# TLE985x register map
Vendor: Infineon Technologies AG; File version: 1.3
CPU: CM0 r0p0, little endian, no MPU, no FPU, 2 interrupt priority bits
Registers are 32-bit, read-write, no defined reset value unless marked. A register's access mark holds for its fields unless they carry their own. Offsets are from the block's base; [hi:lo] are bit positions; {n}, {i} and the like mark numbered series; 'fields as' and 'values as' point back to an identical list.

## CCU6
Base 0x4000C000
0x00 CC63R ro — Capture/Compare Register for Channel CC63
  [15:0] CCV — Channel CC63 Compare Value Low Byte
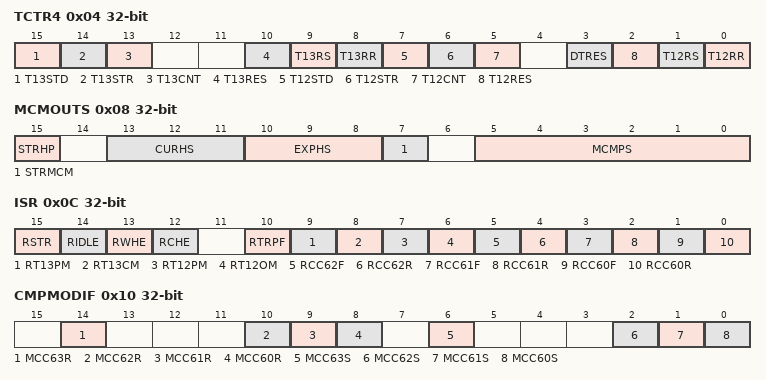
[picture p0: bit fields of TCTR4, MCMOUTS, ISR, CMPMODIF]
0x04 TCTR4 wo — Timer Control Register 4
  [15] T13STD — Timer T13 Shadow Transfer Disable
    0=No action; 1=STE13 reset (STE13 is reset without triggering the shadow transfer.)
  [14] T13STR — Timer T13 Shadow Transfer Request
    0=No action; 1=STE13 set (STE13 is set, enabling the shadow transfer.)
  [13] T13CNT — Timer T13 Count Event
    0=No action; 1=Count (If enabled (PISEL2), timer T13 counts one step.)
  [10] T13RES — Timer T13 Reset
    0=No effect on T13; 1=Zero (The T13 counter register is reset to zero. The switching of the output signals is according to the switching rules. Setting of T13RES has no impact on bit T13R.)
  [9] T13RS — Timer T13 Run Set
    0=No influence (T13R is not influenced.); 1=T13R set (T13R is set, T13 counts.)
  [8] T13RR — Timer T13 Run Reset
    0=No influence (T13R is not influenced.); 1=T13R cleared (T13R is cleared, T13 stops counting.)
  [7] T12STD — Timer T12 Shadow Transfer Disable
    0=No action; 1=STE12 reset (STE12 is reset without triggering the shadow transfer.)
  [6] T12STR — Timer T12 Shadow Transfer Request
    0=No action; 1=STE12 set (STE12 is set, enabling the shadow transfer.)
  [5] T12CNT — Timer T12 Count Event
    0=No action; 1=Count (If enabled (PISEL2), timer T12 counts one step.)
  [3] DTRES — Dead-Time Counter Reset
    0=No effect on the dead-time counters; 1=Zero (The three dead-time counter channels are reset to zero.)
  [2] T12RES — Timer T12 Reset
    0=No effect on T12; 1=Zero (The T12 counter register is reset to zero. The switching of the output signals is according to the switching rules. Setting of T12RES has no impact on bit T12R.)
  [1] T12RS — Timer T12 Run Set
    0=No influence (T12R is not influenced.); 1=T12R set (T12R is set, T12 counts.)
  [0] T12RR — Timer T12 Run Reset
    0=No influence (T12R is not influenced.); 1=T12R cleared (T12R is cleared, T12 stops counting.)
0x08 MCMOUTS access per field — Multi-Channel Mode Output Shadow Register
  [15] STRHP wo — Shadow Transfer Request for the Hall Pattern
    0=by Hardware (The bit fields CURH and EXPH are updated according to the defined hardware action. The write access to bit fields CURHS and EXPHS does not modify the bit fields CURH and EXPH.); 1=by Software (The bit fields CURH and EXPH are updated by the value written to the bit fields CURHS and EXPHS.)
  [13:11] CURHS rw — Current Hall Pattern Shadow
  [10:8] EXPHS rw — Expected Hall Pattern Shadow
  [7] STRMCM wo — Shadow Transfer Request for MCMPS
    0=by Hardware (Bit field MCMP is updated according to the defined hardware action. The write access to bit field MCMPS does not modify bit field MCMP.); 1=by Software (Bit field MCMP is updated by the value written to bit field MCMPS.)
  [5:0] MCMPS rw — Multi-Channel PWM Pattern Shadow
0x0C ISR wo — Capture/Compare Interrupt Status Reset Register
  [15] RSTR — Reset STR Flag
    0=No action; 1=Reset (Bit STR in register IS will be reset.)
  [14] RIDLE — Reset IDLE Flag
    0=No action; 1=Reset (Bit IDLE in register IS will be reset.)
  [13] RWHE — Reset Wrong Hall Event Flag
    0=No action; 1=Reset (Bit WHE in register IS will be reset.)
  [12] RCHE — Reset Correct Hall Event Flag
    0=No action; 1=Reset (Bit CHE in register IS will be reset.)
  [10] RTRPF — Reset Trap Flag
    0=No action; 1=Reset (Bit TRPF in register IS will be reset (not taken into account while input CTRAP = 0 and TRPPEN = 1.)
  [9] RT13PM — Reset Timer T13 Period-Match Flag
    0=No action; 1=Reset (Bit T13PM in register IS will be reset.)
  [8] RT13CM — Reset Timer T13 Compare-Match Flag
    0=No action; 1=Reset (Bit T13CM in register IS will be reset.)
  [7] RT12PM — Reset Timer T12 Period-Match Flag
    0=No action; 1=Reset (Bit T12PM in register IS will be reset.)
  [6] RT12OM — Reset Timer T12 One-Match Flag
    0=No action; 1=Reset (Bit T12OM in register IS will be reset.)
  [5] RCC62F — Reset Capture, Compare-Match Falling Edge Flag
    0=No action; 1=Reset (Bit CC62F in register IS will be reset.)
  [4] RCC62R — Reset Capture, Compare-Match Rising Edge Flag
    0=No action; 1=Reset (Bit CC62R in register IS will be reset.)
  [3] RCC61F — Reset Capture, Compare-Match Falling Edge Flag
    0=No action; 1=Reset (Bit CC61F in register IS will be reset.)
  [2] RCC61R — Reset Capture, Compare-Match Rising Edge Flag
    0=No action; 1=Reset (Bit CC61R in register IS will be reset.)
  [1] RCC60F — Reset Capture, Compare-Match Falling Edge Flag
    0=No action; 1=Reset (Bit CC60F in register IS will be reset.)
  [0] RCC60R — Reset Capture, Compare-Match Rising Edge Flag
    0=No action; 1=Reset (Bit CC60R in register IS will be reset.)
0x10 CMPMODIF wo — Compare State Modification Register
  [14] MCC63R — Capture/Compare Status Modification Bits (Reset)
    0=Not_changed (Bit CC63ST is not changed.); 1=Set (Bit CC63ST is set.); 2=Reset (Bit CC63ST is reset.)
  [10] MCC62R — Capture/Compare Status Modification Bit 2(Reset)
    0=Not_changed (Bit CC62ST is not changed.); 1=Set (Bit CC62ST is set.); 2=Reset (Bit CC62ST is reset.)
  [9] MCC61R — Capture/Compare Status Modification Bit 1(Reset)
    0=Not_changed (Bit CC61ST is not changed.); 1=Set (Bit CC61ST is set.); 2=Reset (Bit CC61ST is reset.)
  [8] MCC60R — Capture/Compare Status Modification Bit 0(Reset)
    0=Not_changed (Bit CC60ST is not changed.); 1=Set (Bit CC60ST is set.); 2=Reset (Bit CC60ST is reset.)
  [6] MCC63S — Capture/Compare Status Modification Bits (Set)
    values as MCC63R
  [2] MCC62S — Capture/Compare Status Modification Bit 2 (Set)
    values as MCC62R
  [1] MCC61S — Capture/Compare Status Modification Bit 1 (Set)
    values as MCC61R
  [0] MCC60S — Capture/Compare Status Modification Bit 0 (Set)
    values as MCC60R
0x14 CC60SR — Capture/Compare Shadow Register for Channel CC60
  [15:0] CCS — Shadow Register for Channel 0 Capture/Compare Value
0x18 CC61SR — Capture/Compare Shadow Register for Channel CC61
  [15:0] CCS — Shadow Register for Channel 1 Capture/Compare Value
0x1C CC62SR — Capture/Compare Shadow Register for Channel CC62
  [15:0] CCS — Shadow Register for Channel 2 Capture/Compare Value
0x20 CC63SR — Capture/Compare Shadow Register for Channel CC63
  [15:0] CCS — Shadow Register for Channel CC63 Compare Value
0x24 T12PR — Timer T12 Period Register
  [15:0] T12PV — T12 Period Value
0x28 T13PR — Timer T13 Period Register
  [15:0] T13PV — T13 Period Value
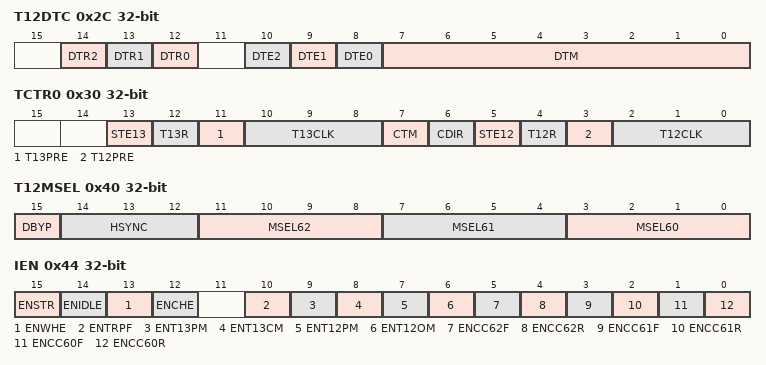
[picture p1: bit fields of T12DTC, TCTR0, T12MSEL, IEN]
0x2C T12DTC access per field — Dead-Time Control Register for Timer T12 Low
  [14] DTR2 ro — Dead-Time Run Indication Bit 2
    0=Zero (The value of the corresponding dead-time counter channel is 0.); 1=Not Zero (The value of the corresponding dead-time counter channel is not 0.)
  [13] DTR1 ro — Dead-Time Run Indication Bit 1
    values as DTR2
  [12] DTR0 ro — Dead-Time Run Indication Bit 0
    values as DTR2
  [10] DTE2 rw — Dead-Time Enable Bit 2
    0=Disabled (Dead-time generation is disabled. The corresponding outputs switch from the passive state to the active state (according to the actual compare status) without any delay.); 1=Enabled (Dead-time generation is enabled. The corresponding outputs switch from the passive state to the active state (according to the compare status) with the delay programmed in bit field DTM.)
  [9] DTE1 rw — Dead-Time Enable Bit 1
    values as DTE2
  [8] DTE0 rw — Dead-Time Enable Bit 0
    values as DTE2
  [7:0] DTM rw — Dead-Time
0x30 TCTR0 access per field — Timer Control Register 0
  [13] STE13 ro — Timer T13 Shadow Transfer Enable
    0=Disabled (The shadow register transfer is disabled.); 1=Enabled (The shadow register transfer is enabled.)
  [12] T13R ro — Timer T13 Run Bit
    0=Stop (Timer T13 is stopped.); 1=Run (Timer T13 is running.)
  [11] T13PRE rw — Timer T13 Prescaler Bit
    0=Disabled (The additional prescaler for T13 is disabled.); 1=Enabled (The additional prescaler for T13 is enabled.)
  [10:8] T13CLK rw — Timer T13 Input Clock Select
    0=fT13 = fCCU; 1=fT13 = fCCU / 2; 2=fT13 = fCCU / 4; 3=fT13 = fCCU / 8; 4=fT13 = fCCU / 16; 5=fT13 = fCCU / 32; 6=fT13 = fCCU / 64; 7=fT13 = fCCU / 128
  [7] CTM rw — T12 Operating Mode
    0=Edge-aligned Mode (T12 always counts up and continues counting from zero after reaching the period value.); 1=Center-aligned Mode (T12 counts down after detecting a period-match and counts up after detecting a one-match.)
  [6] CDIR ro — Count Direction of Timer T12
    0=UP (T12 counts up.); 1=DOWN (T12 counts down.)
  [5] STE12 ro — Timer T12 Shadow Transfer Enable
    values as STE13
  [4] T12R ro — Timer T12 Run Bit
    0=Stop (Timer T12 is stopped.); 1=Run (Timer T12 is running.)
  [3] T12PRE rw — Timer T12 Prescaler Bit
    0=Disabled (The additional prescaler for T12 is disabled.); 1=Enabled (The additional prescaler for T12 is enabled.)
  [2:0] T12CLK rw — Timer T12 Input Clock Select
    0=fT12 = fCCU; 1=fT12 = fCCU / 2; 2=fT12 = fCCU / 4; 3=fT12 = fCCU / 8; 4=fT12 = fCCU / 16; 5=fT12 = fCCU / 32; 6=fT12 = fCCU / 64; 7=fT12 = fCCU / 128
0x34 CC60R ro — Capture/Compare Register for Channel CC60
  [15:0] CCV — Channel 0 Capture/Compare Value
0x38 CC61R ro — Capture/Compare Register for Channel CC61
  [15:0] CCV — Channel 1 Capture/Compare Value
0x3C CC62R ro — Capture/Compare Register for Channel CC62
  [15:0] CCV — Channel 2 Capture/Compare Value
0x40 T12MSEL — T12 Capture/Compare Mode Select Register
  [15] DBYP — Delay Bypass
    0=Not active (The delay bypass is not active. The dead-time counter DTC0 is generating a delay after the source signal becomes active.); 1=Active (The delay bypass is active. The dead-time counter DTC0 is not used by the sampling of the Hall pattern.)
  [14:12] HSYNC — Hall Synchronization
    0=Any (Any edge at one of the inputs CCPOSx (x = 0, 1, 2) triggers the sampling.); 1=T13 compare-match (A T13 compare-match triggers the sampling.); 2=T13 period-match (A T13 period-match triggers the sampling.); 3=Hall (The Hall sampling triggered by hardware sources is switched off.); 4=T12 period-match (A T12 period-match (while counting up) triggers the sampling.); 5=T12 one-match (A T12 one-match (while counting down) triggers the sampling.); 6=T12 compare-match UP (A T12 compare-match of channel 0 (while counting up) triggers the sampling.); 7=T12 compare-match DOWN (A T12 compare-match of channel 0 (while counting down) triggers the sampling.)
  [11:8] MSEL62 — Capture/Compare Mode Selection
    0=Compare outputs disabled, pins CC6n and COUT6n can be used for I/O. No capture action.; 1=Pin CC6n, pin COUT6n (Compare output on pin CC6n, pin COUT6n can be used for I/O. No capture action.); 2=Pin COUT6n, Pin CC6n (Compare output on pin COUT6n, pin CC6n can be used for I/O. No capture action.); 3=Pins COUT6n and CC6n (Compare output on pins COUT6n and CC6n.); 0b01XX=Double-Register Capture modes (see .); 8=Hall Sensor mode (see . In order to enable the hall edge detection, all three MSEL6x must be programmed to Hall Sensor mode.); 9=Hysteresis-like_mode (see .); 0b101X=Multi-Input_Capture_modes (see .); 0b11XX=Multi-Input_Capture_modes (see .)
  [7:4] MSEL61 — Capture/Compare Mode Selection
    0=Compare outputs disabled, pins CC6n and COUT6n can be used for I/O. No capture action.; 1=Pin CC6n, pin COUT6n (Compare output on pin CC6n, pin COUT6n can be used for I/O. No capture action.); 2=Pin COUT6n, Pin CC6n (Compare output on pin COUT6n, pin CC6n can be used for I/O. No capture action.); 3=Pins COUT6n and CC6n (Compare output on pins COUT6n and CC6n.); 0b01XX=Double-Register Capture modes (see .); 8=Hysteresis-like_mode (see . In order to enable the hall edge detection, all three MSEL6x must be programmed to Hall Sensor mode.); 0b11XX=Multi-Input_Capture_modes (see .)
  [3:0] MSEL60 — Capture/Compare Mode Selection
    values as MSEL61
0x44 IEN — Capture/Compare Interrupt Enable Register
  [15] ENSTR — Enable Multi-Channel Mode Shadow Transfer Interrupt
    0=No interrupt will be generated if the set condition for bit STR in register IS occurs; 1=Interrupt (An interrupt will be generated if the set condition for bit STR in register IS occurs. The interrupt line that will be activated is selected by bit field INPCHE.)
  [14] ENIDLE — Enable Idle
    0=IDLE not set (The bit IDLE is not automatically set when a wrong hall event is detected.); 1=IDLE set (The bit IDLE is automatically set when a wrong hall event is detected.)
  [13] ENWHE — Enable Interrupt for Wrong Hall Event
    0=No interrupt will be generated if the set condition for bit WHE in register IS occurs; 1=Interrupt (An interrupt will be generated if the set condition for bit WHE in register IS occurs. The interrupt line that will be activated is selected by bit field INPERR.)
  [12] ENCHE — Enable Interrupt for Correct Hall Event
    0=No interrupt will be generated if the set condition for bit CHE in register IS occurs; 1=Interrupt (An interrupt will be generated if the set condition for bit CHE in register IS occurs. The interrupt line that will be activated is selected by bit field INPCHE.)
  [10] ENTRPF — Enable Interrupt for Trap Flag
    0=No interrupt will be generated if the set condition for bit TRPF in register IS occurs; 1=Interrupt (An interrupt will be generated if the set condition for bit TRPF in register IS occurs. The interrupt line that will be activated is selected by bit field INPERR.)
  [9] ENT13PM — Enable Interrupt for T13 Period-Match
    0=No interrupt will be generated if the set condition for bit T13PM in register IS occurs; 1=Interrupt (An interrupt will be generated if the set condition for bit T13PM in register IS occurs. The interrupt line that will be activated is selected by bit field INPT13.)
  [8] ENT13CM — Enable Interrupt for T13 Compare-Match
    0=No interrupt will be generated if the set condition for bit T13CM in register IS occurs; 1=Interrupt (An interrupt will be generated if the set condition for bit T13CM in register IS occurs. The interrupt line that will be activated is selected by bit field INPT13.)
  [7] ENT12PM — Enable Interrupt for T12 Period-Match
    0=No interrupt will be generated if the set condition for bit T12PM in register IS occurs; 1=Interrupt (An interrupt will be generated if the set condition for bit T12PM in register IS occurs. The interrupt line that will be activated is selected by bit field INPT12.)
  [6] ENT12OM — Enable Interrupt for T12 One-Match
    0=No interrupt will be generated if the set condition for bit T12OM in register IS occurs; 1=Interrupt (An interrupt will be generated if the set condition for bit T12OM in register IS occurs. The interrupt line that will be activated is selected by bit field INPT12.)
  [5] ENCC62F — Capture, Compare-Match Falling Edge Interrupt Enable for Channel 2
    0=No interrupt will be generated if the set condition for bit CC62F in register IS occurs; 1=Interrupt (An interrupt will be generated if the set condition for bit CC62F in register IS occurs. The interrupt line that will be activated is selected by bit field INPCC62.)
  [4] ENCC62R — Capture, Compare-Match Rising Edge Interrupt Enable for Channel 2
    0=No interrupt will be generated if the set condition for bit CC62R in register IS occurs; 1=Interrupt (An interrupt will be generated if the set condition for bit CC62R in register IS occurs. The interrupt line that will be activated is selected by bit field INPCC62.)
  [3] ENCC61F — Capture, Compare-Match Falling Edge Interrupt Enable for Channel 1
    0=No interrupt will be generated if the set condition for bit CC61F in register IS occurs; 1=Interrupt (An interrupt will be generated if the set condition for bit CC61F in register IS occurs. The interrupt line that will be activated is selected by bit field INPCC61.)
  [2] ENCC61R — Capture, Compare-Match Rising Edge Interrupt Enable for Channel 1
    0=No interrupt will be generated if the set condition for bit CC61R in register IS occurs; 1=Interrupt (An interrupt will be generated if the set condition for bit CC61R in register IS occurs. The interrupt line that will be activated is selected by bit field INPCC61.)
  [1] ENCC60F — Capture, Compare-Match Falling Edge Interrupt Enable for Channel 0
    0=No interrupt will be generated if the set condition for bit CC60F in register IS occurs; 1=Interrupt (An interrupt will be generated if the set condition for bit CC60F in register IS occurs. The interrupt line that will be activated is selected by bit field INPCC60.)
  [0] ENCC60R — Capture, Compare-Match Rising Edge Interrupt Enable for Channel 0
    0=No interrupt will be generated if the set condition for bit CC60R in register IS occurs; 1=Interrupt (An interrupt will be generated if the set condition for bit CC60R in register IS occurs. The interrupt line that will be activated is selected by bit field INPCC60.)
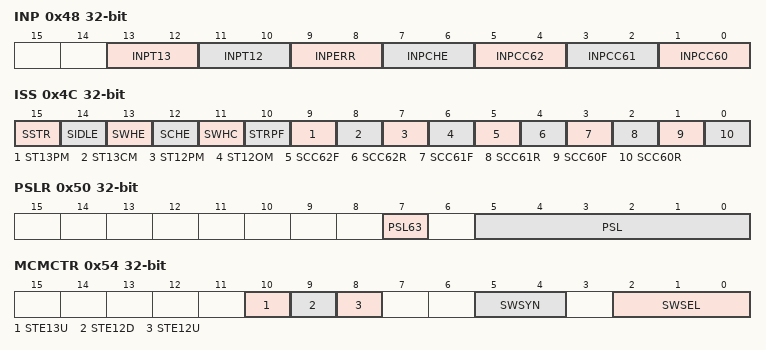
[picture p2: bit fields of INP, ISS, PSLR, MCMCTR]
0x48 INP — Capture/Compare Interrupt Node Pointer Register
  [all] fields
    {v}=SR{v} (Interrupt output line SR{v} is selected.) (v=0..3)
  [13:12] INPT13 — Interrupt Node Pointer for Timer T13 Interrupts
  [11:10] INPT12 — Interrupt Node Pointer for Timer T12 Interrupts
  [9:8] INPERR — Interrupt Node Pointer for Error Interrupts
  [7:6] INPCHE — Interrupt Node Pointer for the CHE Interrupt
  [5:4] INPCC62 — Interrupt Node Pointer for Channel 2 Interrupts
  [3:2] INPCC61 — Interrupt Node Pointer for Channel 1 Interrupts
  [1:0] INPCC60 — Interrupt Node Pointer for Channel 0 Interrupts
0x4C ISS wo — Capture/Compare Interrupt Status Set Register
  [15] SSTR — Set STR Flag
    0=No action; 1=Set (Bit STR in register IS will be set.)
  [14] SIDLE — Set IDLE Flag
    0=No action; 1=Set (Bit IDLE in register IS will be set.)
  [13] SWHE — Set Wrong Hall Event Flag
    0=No action; 1=Set (Bit WHE in register IS will be set.)
  [12] SCHE — Set Correct Hall Event Flag
    0=No action; 1=Set (Bit CHE in register IS will be set.)
  [11] SWHC — Software Hall Compare
    0=No action; 1=Set (The Hall compare action is triggered.)
  [10] STRPF — Set Trap Flag
    0=No action; 1=Set (Bits TRPF and TRPS in register IS will be set.)
  [9] ST13PM — Set Timer T13 Period-Match Flag
    0=No action; 1=Set (Bit T13PM in register IS will be set.)
  [8] ST13CM — Set Timer T13 Compare-Match Flag
    0=No action; 1=Set (Bit T13CM in register IS will be set.)
  [7] ST12PM — Set Timer T12 Period-Match Flag
    0=No action; 1=Set (Bit T12PM in register IS will be set.)
  [6] ST12OM — Set Timer T12 One-Match Flag
    0=No action; 1=Set (Bit T12OM in register IS will be set.)
  [5] SCC62F — Set Capture, Compare-Match Falling Edge Flag
    0=No action; 1=Set (Bit CC62F in register IS will be set.)
  [4] SCC62R — Set Capture, Compare-Match Rising Edge Flag
    0=No action; 1=Set (Bit CC62R in register IS will be set.)
  [3] SCC61F — Set Capture, Compare-Match Falling Edge Flag
    0=No action; 1=Set (Bit CC61F in register IS will be set.)
  [2] SCC61R — Set Capture, Compare-Match Rising Edge Flag
    0=No action; 1=Set (Bit CC61R in register IS will be set.)
  [1] SCC60F — Set Capture, Compare-Match Falling Edge Flag
    0=No action; 1=Set (Bit CC60F in register IS will be set.)
  [0] SCC60R — Set Capture, Compare-Match Rising Edge Flag
    0=No action; 1=Set (Bit CC60R in register IS will be set.)
0x50 PSLR — Passive State Level Register
  [7] PSL63 — Passive State Level of Output COUT63
    0=Level 0 (The passive level is 0.); 1=Level 1 (The passive level is 1.)
  [5:0] PSL — Compare Outputs Passive State Level
    values as PSL63
0x54 MCMCTR — Multi-Channel Mode Control Register
  [10] STE13U — Shadow Transfer Enable for T13 Upcounting
    0=No action; 1=Enabled (The T13_ST shadow transfer mechanism is enabled if MCMEN = 1.)
  [9] STE12D — Shadow Transfer Enable for T12 Downcounting
    0=No action; 1=Enabled (The T12_ST shadow transfer mechanism is enabled if MCMEN = 1.)
  [8] STE12U — Shadow Transfer Enable for T12 Upcounting
    values as STE12D
  [5:4] SWSYN — Switching Synchronization
    0=Direct (the trigger event directly causes the shadow transfer); 1=T13 zero-match triggers the shadow transfer; 2=T12 zero-match (a T12 zero-match (while counting up) triggers the shadow transfer)
  [2:0] SWSEL — Switching Selection
    0=No request (no trigger request will be generated); 1=Correct pattern (correct hall pattern on CCPOSx detected); 2=T13 period-match detected (while counting up); 3=T12 one-match (while counting down); 4=T12 channel 1 compare-match detected (phase delay function); 5=T12 period match detected (while counting up) else reserved, no trigger request will be generated
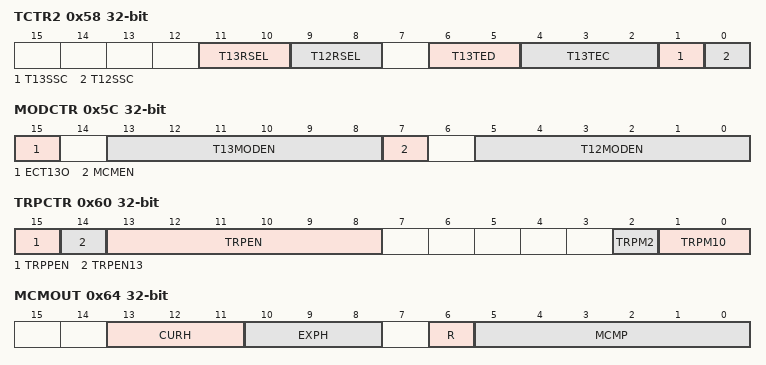
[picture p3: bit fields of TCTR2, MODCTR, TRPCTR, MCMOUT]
0x58 TCTR2 — Timer Control Register 2
  [11:10] T13RSEL — Timer T13 External Run Selection
    0=Disabled (The external setting of T13R is disabled.); 1=Rising edge (Bit T13R is set if a rising edge of signal T13HR is detected.); 2=Falling edge (Bit T13R is set if a falling edge of signal T13HR is detected.); 3=Edge (Bit T13R is set if an edge of signal T13HR is detected.)
  [9:8] T12RSEL — Timer T12 External Run Selection
    0=Disabled (The external setting of T12R is disabled.); 1=Rising edge (Bit T12R is set if a rising edge of signal T12HR is detected.); 2=Falling edge (Bit T12R is set if a falling edge of signal T12HR is detected.); 3=Edge (Bit T12R is set if an edge of signal T12HR is detected.)
  [6:5] T13TED — Timer T13 Trigger Event Direction
    0=No action; 1=Up (while T12 is counting up); 2=Down (while T12 is counting down); 3=independent on the count direction of T12
  [4:2] T13TEC — T13 Trigger Event Control
    0=No action; 1=Channel 0 (set T13R on a T12 compare event on channel 0); 2=Channel 1 (set T13R on a T12 compare event on channel 1); 3=Channel 2 (set T13R on a T12 compare event on channel 2); 4=Channel 0,1,2 (set T13R on any T12 compare event on the channels 0, 1, or 2); 5=Period-match (set T13R upon a period-match of T12); 6=Zero-match (set T13R upon a zero-match of T12 (while counting up)); 7=CCPOSx (set T13R on any edge of inputs CCPOSx)
  [1] T13SSC — Timer T13 Single Shot Control
    0=No action (No hardware action on T13R); 1=Enabled (The single-shot mode is enabled, the bit T13R is reset by hardware if T13 reaches its period value. In parallel to the reset action of bit T13R, the bit CC63ST is reset.)
  [0] T12SSC — Timer T12 Single Shot Control
    0=Disabled (The single-shot mode is disabled, no hardware action on T12R.); 1=Enabled (The single shot mode is enabled, the bit T12R is reset by hardware if: - T12 reaches its period value in edge-aligned mode - T12 reaches the value 1 while down counting in center-aligned mode. In parallel to the reset action of bit T12R, the bits CC6xST (x = 0, 1, 2) are reset.)
0x5C MODCTR — Modulation Control Register
  [15] ECT13O — Enable Compare Timer T13 Output
    0=Disabled (The alternate output function COUT63 is disabled.); 1=Enabled (The alternate output function COUT63 is enabled for the PWM signal generated by T13.)
  [13:8] T13MODEN — T13 Modulation Enable
    0=Disabled (The modulation of the corresponding output signal by a T13 PWM pattern is disabled.); 1=Enabled (The modulation of the corresponding output signal by a T13 PWM pattern is enabled.)
  [7] MCMEN — Multi-Channel Mode Enable
    0=Disabled (The modulation of the corresponding output signal by a multi-channel pattern according to bit field MCMOUT is disabled.); 1=Enabled (The modulation of the corresponding output signal by a multi-channel pattern according to bit field MCMOUT is enabled.)
  [5:0] T12MODEN — T12 Modulation Enable
    0=Disabled (The modulation of the corresponding output signal by a T12 PWM pattern is disabled.); 1=Enabled (The modulation of the corresponding output signal by a T12 PWM pattern is enabled.)
0x60 TRPCTR — Trap Control Register
  [15] TRPPEN — Trap Pin Enable
    0=Disabled (The trap functionality based on the input pin CTRAP is disabled. A trap can only be generated by software by setting bit TRPF.); 1=Enabled (The trap functionality based on the input pin CTRAP is enabled. A trap can be generated by software by setting bit TRPF or by CTRAP = 0.)
  [14] TRPEN13 — Trap Enable Control for Timer T13
    0=Disabled (The trap functionality for T13 is disabled. Timer T13 (if selected and enabled) provides PWM functionality even while TRPS = 1.); 1=Enabled (The trap functionality for T13 is enabled. The timer T13 PWM output signal is set to the passive state while TRPS = 1.)
  [13:8] TRPEN — Trap Enable Control
    0=Disabled (The trap functionality of the corresponding output signal is disabled. The output state is independent from bit TRPS.); 1=Enabled (The trap functionality of the corresponding output signal is enabled. The output is set to the passive state while TRPS = 1.)
  [2] TRPM2 — Trap Mode Control Bit 2
    0=Hardware reset (The trap state can be left (return to normal operation = bit TRPS = 0) as soon as the input CTRAP becomes inactive. Bit TRPF is automatically cleared by hardware if the input pin CTRAP becomes 1. Bit TRPS is automatically cleared by hardware if bit TRPF is 0 and if the synchronization condition (according to TRPM10) is detected.); 1=Software reset (The trap state can be left (return to normal operation = bit TRPS = 0) as soon as bit TRPF is reset by software after the input CTRAP becomes inactive (TRPF is not cleared by hardware). Bit TRPS is automatically cleared by hardware if bit TRPF = 0 and if the synchronization condition (according to TRPM10) is detected.)
  [1:0] TRPM10 — Trap Mode Control Bits 1, 0
    0=T12 zero-match (The trap state is left (return to normal operation according to TRPM2) when a zero-match of T12 (while counting up) is detected (synchronization to T12).); 1=T13 zero-match (The trap state is left (return to normal operation according to TRPM2) when a zero-match of T13 is detected (synchronization to T13).); 3=Immediately (The trap state is left (return to normal operation according to TRPM2) immediately without any synchronization to T12 or T13.)
0x64 MCMOUT ro — Multi-Channel Mode Output Register
  [13:11] CURH — Current Hall Pattern
  [10:8] EXPH — Expected Hall Pattern
  [6] R — Reminder Flag
    0=No shadow transfer (Currently, no shadow transfer from MCMPS to MCMP is requested.); 1=Shadow transfer (A shadow transfer from MCMPS to MCMP has been requested by the selected trigger source, but it has not yet been executed, because the selected synchronization condition has not yet occurred.)
  [5:0] MCMP — Multi-Channel PWM Pattern
    0=Passive (The output is set to the passive state. The PWM generated by T12 or T13 is not taken into account.); 1=PWM (The output can deliver the PWM generated by T12 or T13 (according to register MODCTR).)
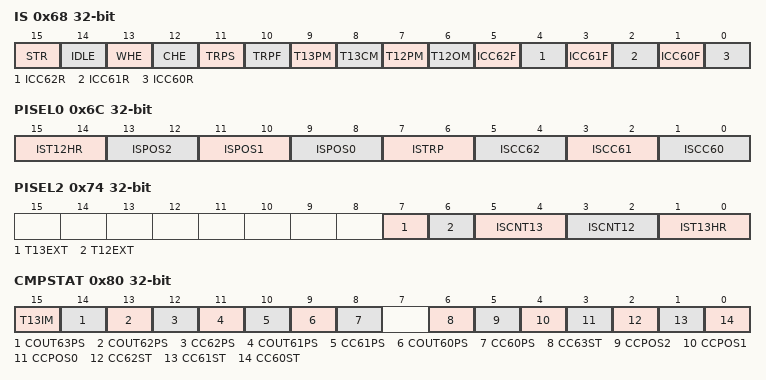
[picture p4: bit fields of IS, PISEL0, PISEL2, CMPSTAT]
0x68 IS ro — Capture/Compare Interrupt Status Register
  [15] STR — Multi-Channel Mode Shadow Transfer Request
    0=No (The shadow transfer has not yet taken place.); 1=Yes (The shadow transfer has taken place.)
  [14] IDLE — IDLE State
    0=No action; 1=Idle (Bit field MCMP is cleared and held to 0, the selected outputs are set to passive state.)
  [13] WHE — Wrong Hall Event
    0=Not detected (A transition to a wrong hall event (not the expected one) has not yet been detected since this bit has been reset for the last time.); 1=Detected (A transition to a wrong hall event (not the expected one) has been detected.)
  [12] CHE — Correct Hall Event
    0=Not detected (A transition to a correct (= expected) hall event has not yet been detected since this bit has been reset for the last time.); 1=Detected (A transition to a correct (= expected) hall event has been detected.)
  [11] TRPS — Trap State
    0=Not active (The trap state is not active.); 1=Active (The trap state is active. Bit TRPS is set while bit TRPF = 1. It is reset according to the mode selected in register TRPCTR.)
  [10] TRPF — Trap Flag
    0=Not detected (The trap condition has not been detected.); 1=Detected (The trap condition has been detected (input CTRAP has been 0 or by software).)
  [9] T13PM — Timer T13 Period-Match Flag
    0=Not detected (A timer T13 period-match has not yet been detected since this bit has been reset for the last time.); 1=Detected (A timer T13 period-match has been detected.)
  [8] T13CM — Timer T13 Compare-Match Flag
    0=Not detected (A timer T13 compare-match has not yet been detected since this bit has been reset for the last time.); 1=Detected (A timer T13 compare-match has been detected.)
  [7] T12PM — Timer T12 Period-Match Flag
    0=Not detected (A timer T12 period-match (while counting up) has not yet been detected since this bit has been reset for the last time.); 1=Detected (A timer T12 period-match (while counting up) has been detected.)
  [6] T12OM — Timer T12 One-Match Flag
    0=Not detected (A timer T12 one-match (while counting down) has not yet been detected since this bit has been reset for the last time.); 1=Detected (A timer T12 one-match (while counting down) has been detected.)
  [5] ICC62F — Capture, Compare-Match Falling Edge Flag
    0=Not occurred (The event has not yet occurred since this bit has been reset for the last time.); 1=Detected (The event described above has been detected.)
  [4] ICC62R — Capture, Compare-Match Rising Edge Flag
    values as ICC62F
  [3] ICC61F — Capture, Compare-Match Falling Edge Flag
    values as ICC62F
  [2] ICC61R — Capture, Compare-Match Rising Edge Flag
    values as ICC62F
  [1] ICC60F — Capture, Compare-Match Falling Edge Flag
    values as ICC62F
  [0] ICC60R — Capture, Compare-Match Rising Edge Flag
    values as ICC62F
0x6C PISEL0 — Port Input Select Register 0
  [15:14] IST12HR — Input Select for T12HR
    0=T12HRA (Either signal T12HRA (if T12EXT = 0) or T12HRE (if T12EXT = 1) is selected.); 1=T12HRB (Either signal T12HRB (if T12EXT = 0) or T12HRF (if T12EXT = 1) is selected.); 2=T12HRC (Either signal T12HRC (if T12EXT = 0) or T12HRG (if T12EXT = 1) is selected.); 3=T12HRD (Either signal T12HRD (if T12EXT = 0) or T12HRH (if T12EXT = 1) is selected.)
  [13:12] ISPOS2 — Input Select for CCPOS2
    0=CCPOS2_0 (The input pin for CCPOS2_0.); 1=CCPOS2_1 (The input pin for CCPOS2_1.); 2=CCPOS2_2 (The input pin for CCPOS2_2.)
  [11:10] ISPOS1 — Input Select for CCPOS1
    0=CCPOS1_0 (The input pin for CCPOS1_0.); 1=CCPOS1_1 (The input pin for CCPOS1_1.); 2=CCPOS1_2 (The input pin for CCPOS1_2.)
  [9:8] ISPOS0 — Input Select for CCPOS0
    0=CCPOS0_0 (The input pin for CCPOS0_0.); 1=CCPOS0_1 (The input pin for CCPOS0_1.); 2=CCPOS0_2 (The input pin for CCPOS0_2.)
  [7:6] ISTRP — Input Select for CTRAP
    0=CTRAP_0 (The input pin for CTRAP_0.); 1=CTRAP_1 (The input pin for CTRAP_1.); 2=CTRAP_2 (The input pin for CTRAP_2.); 3=DU1_UP_STS (The output DU1_UP_STS of the Differential Measurement Unit is selected.)
  [5:4] ISCC62 — Input Select for CC62
    0=CC62_0 (The input pin for CC62_0.); 1=CC62_1 (The input pin for CC62_1.)
  [3:2] ISCC61 — Input Select for CC61
    0=CC61_0 (The input pin for CC61_0.); 1=CC61_1 (The input pin for CC61_1.)
  [1:0] ISCC60 — Input Select for CC60
    0=CC60_0 (The input pin for CC60_0.); 1=CC60_1 (The input pin for CC60_1.)
0x74 PISEL2 — Port Input Select Register 2
  [7] T13EXT — Extension for T13HR Inputs
    0=T13HR_D_A (One of the signals T13HR[D:A] is selected.); 1=T13HR_H_E (One of the signals T13HR[H:E] is selected.)
  [6] T12EXT — Extension for T12HR Inputs
    0=T12HR_D_A (One of the signals T12HR[D:A] is selected.); 1=T12HR_H_E (One of the signals T12HR[H:E] is selected.)
  [5:4] ISCNT13 — Input Select for T13 Counting Input
    0=T13 prescaler (The T13 prescaler generates the counting events. Bit TCTR4.T13CNT is not taken into account.); 1=TCTR4.T13CNT (Bit TCTR4.T13CNT written with 1 is a counting event. The T13 prescaler is not taken into account.); 2=Rising edge (The timer T13 is counting each rising edge detected in the selected T13HR signal.); 3=Falling Edge (The timer T13 is counting each falling edge detected in the selected T13HR signal.)
  [3:2] ISCNT12 — Input Select for T12 Counting Input
    0=T12 prescaler (The T12 prescaler generates the counting events. Bit TCTR4.T12CNT is not taken into account.); 1=TCTR4.T12CNT (Bit TCTR4.T12CNT written with 1 is a counting event. The T12 prescaler is not taken into account.); 2=Rising edge (The timer T12 is counting each rising edge detected in the selected T12HR signal.); 3=Falling edge (The timer T12 is counting each falling edge detected in the selected T12HR signal.)
  [1:0] IST13HR — Input Select for T13HR
    0=T13HRA (Either signal T13HRA (if T13EXT = 0) or T13HRE (if T13EXT = 1) is selected.); 1=T13HRB (Either signal T13HRB (if T13EXT = 0) or T13HRF (if T13EXT = 1) is selected.); 2=T13HRC (Either signal T13HRC (if T13EXT = 0) or T13HRG (if T13EXT = 1) is selected.); 3=T13HRD (Either signal T13HRD (if T13EXT = 0) or T13HRH (if T13EXT = 1) is selected.)
0x78 T12 — Timer T12 Counter Register
  [15:0] T12CV — Timer T12 Counter Value
0x7C T13 — Timer T13 Counter Register
  [15:0] T13CV — Timer T13 Counter Value
0x80 CMPSTAT access per field — Compare State Register
  [15] T13IM rw — T13 Inverted Modulation
    0=Not inverted (T13 output is not inverted.); 1=Inverted (T13 output is inverted for further modulation.)
  [14] COUT63PS rw — Passive State Select for Compare Outputs
    0=Zero (The corresponding compare output drives passive level while CC6xST is 0.); 1=One (The corresponding compare output drives passive level while CC6xST is 1.)
  [13] COUT62PS rw — Passive State Select for Compare Outputs
    values as COUT63PS
  [12] CC62PS rw — Passive State Select for Compare Outputs
    values as COUT63PS
  [11] COUT61PS rw — Passive State Select for Compare Outputs
    values as COUT63PS
  [10] CC61PS rw — Passive State Select for Compare Outputs
    values as COUT63PS
  [9] COUT60PS rw — Passive State Select for Compare Outputs
    values as COUT63PS
  [8] CC60PS rw — Passive State Select for Compare Outputs
    values as COUT63PS
  [6] CC63ST ro — Capture/Compare State Bits
    0=Less (In compare mode, the timer count is less than the compare value. In capture mode, the selected edge has not yet been detected since the bit has been reset by software the last time.); 1=Greater (In compare mode, the counter value is greater than or equal to the compare value. In capture mode, the selected edge has been detected.)
  [5] CCPOS2 ro — Sampled Hall Pattern Bit 2
    0=Zero (The input CCPOS2 has been sampled as 0.); 1=One (The input CCPOS2 has been sampled as 1.)
  [4] CCPOS1 ro — Sampled Hall Pattern Bit 1
    0=Zero (The input CCPOS1 has been sampled as 0.); 1=One (The input CCPOS1 has been sampled as 1.)
  [3] CCPOS0 ro — Sampled Hall Pattern Bit 0
    0=Zero (The input CCPOS0 has been sampled as 0.); 1=One (The input CCPOS0 has been sampled as 1.)
  [2] CC62ST ro — Capture/Compare State Bits
    values as CC63ST
  [1] CC61ST ro — Capture/Compare State Bits
    values as CC63ST
  [0] CC60ST ro — Capture/Compare State Bits
    values as CC63ST
